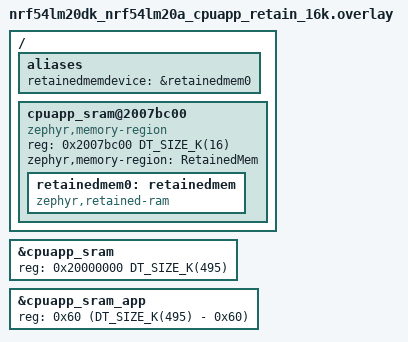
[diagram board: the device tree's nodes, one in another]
/ {
	aliases {
		retainedmemdevice = &retainedmem0;
	};

	cpuapp_sram@2007bc00 {
		compatible = "zephyr,memory-region", "mmio-sram";
		reg = <0x2007bc00 DT_SIZE_K(16)>;
		zephyr,memory-region = "RetainedMem";
		status = "okay";

		retainedmem0: retainedmem {
			compatible = "zephyr,retained-ram";
			status = "okay";
		};
	};
};

&cpuapp_sram {
	/* Shrink SRAM size to avoid overlap with retained memory region:
	 * 511 - 16 = 495KB = 0x7bc00
	 */
	reg = <0x20000000 DT_SIZE_K(495)>;
	ranges = <0x0 0x20000000 0x7bc00>;
};

&cpuapp_sram_app {
	reg = <0x60 (DT_SIZE_K(495) - 0x60)>;
};
